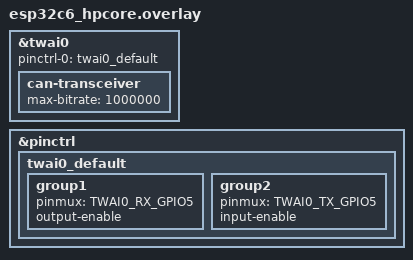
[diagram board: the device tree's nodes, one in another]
/*
 * Copyright (c) 2026 Espressif Systems (Shanghai) Co., Ltd.
 *
 * SPDX-License-Identifier: Apache-2.0
 */

&twai0 {
	status = "okay";
	pinctrl-0 = <&twai0_default>;
	pinctrl-names = "default";

	can-transceiver {
		max-bitrate = <1000000>;
	};
};

&pinctrl {
	twai0_default: twai0_default {
		group1 {
			pinmux = <TWAI0_RX_GPIO5>;
			output-enable;	/* enable internal loopback */
		};

		group2 {
			pinmux = <TWAI0_TX_GPIO5>;
			input-enable;	/* enable internal loopback */
		};
	};
};
